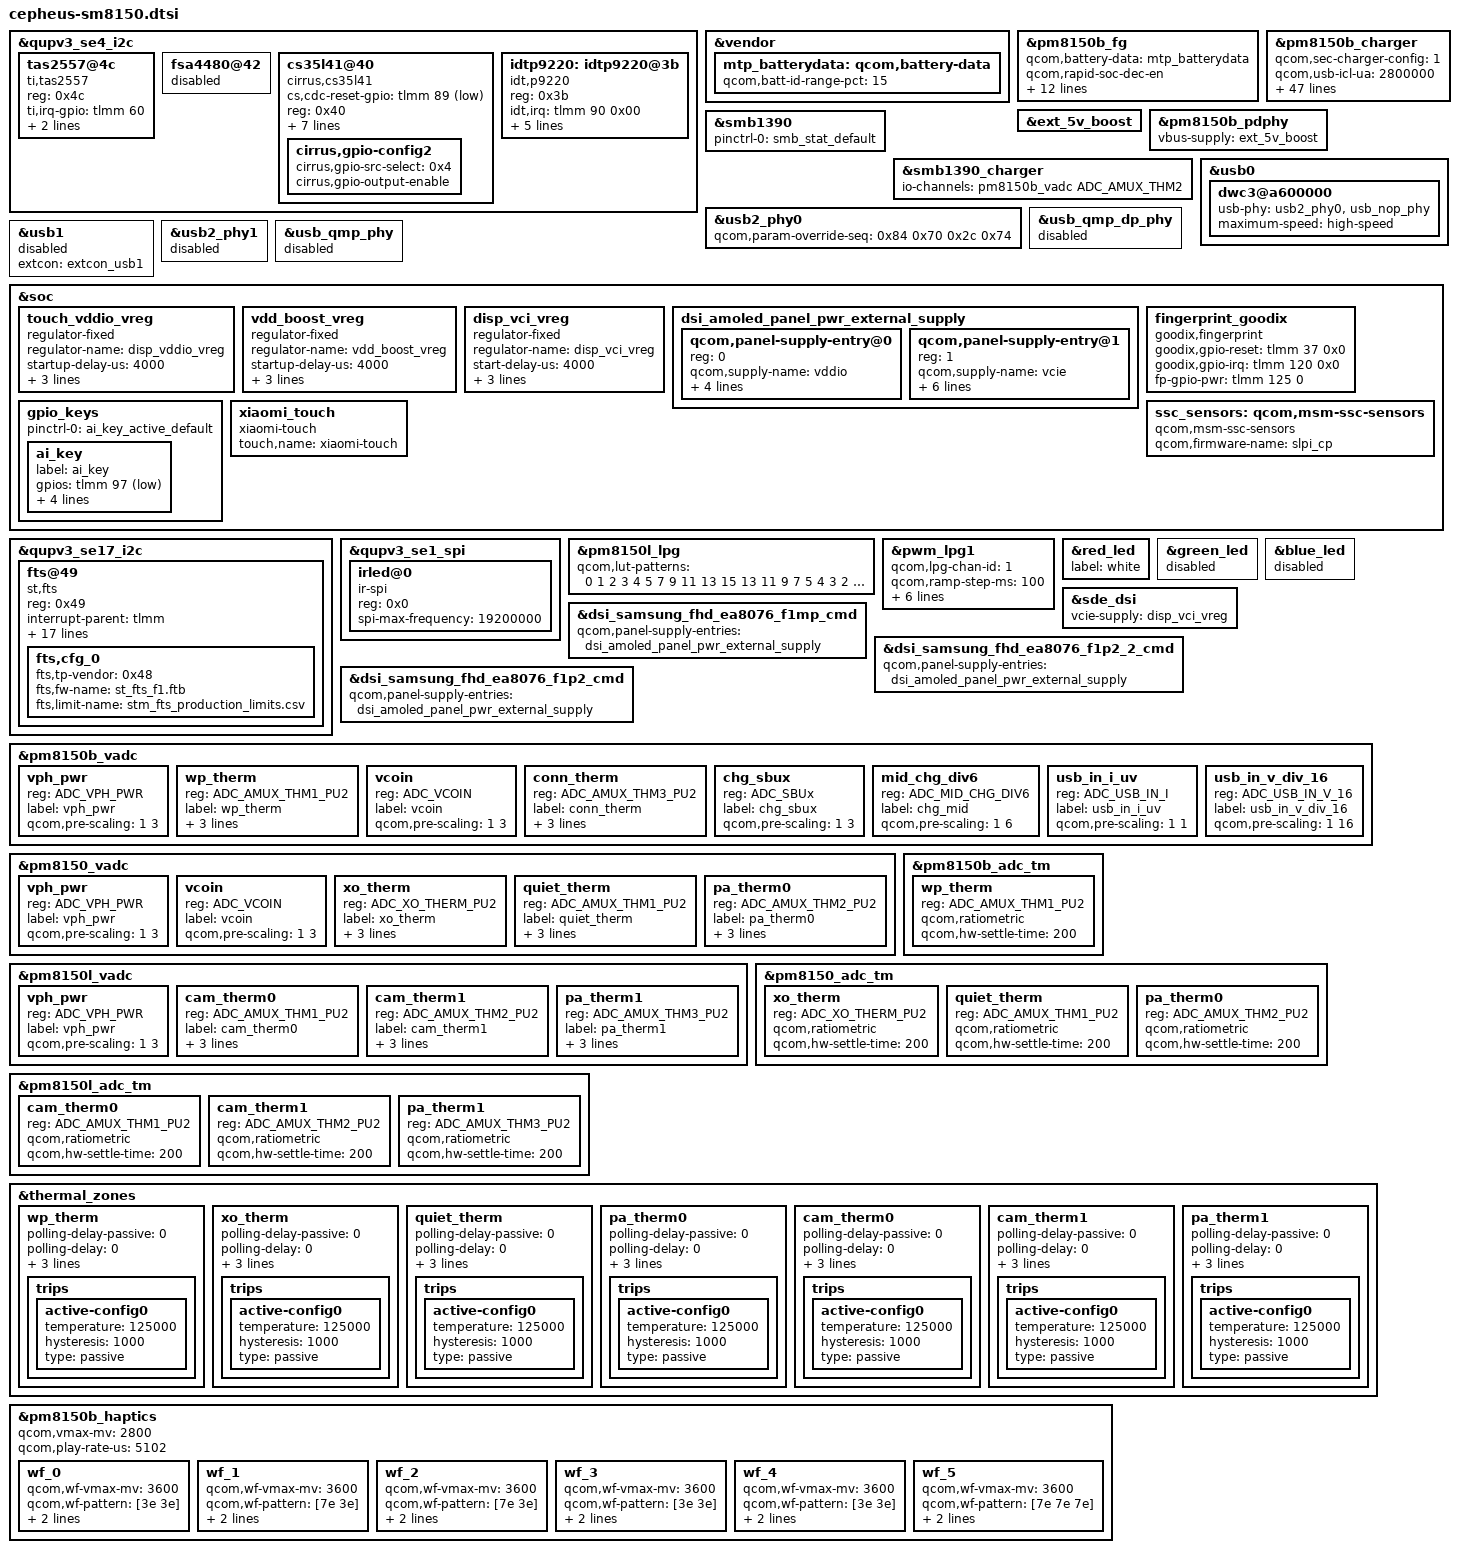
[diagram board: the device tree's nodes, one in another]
/*
this file is for attribution only of cepheus
And public attribution of xiaomi platforms(like F1 and so and)
*/
#include "cepheus-pinctrl.dtsi"
#include "xiaomi-sm8150-common.dtsi"
#include "cepheus-sm8150-camera-sensor-mtp.dtsi"

&qupv3_se4_i2c {
#include "smb1390.dtsi"
};

&vendor {
	mtp_batterydata: qcom,battery-data {
		qcom,batt-id-range-pct = <15>;
		#include "batterydata-F1-atl-3300mah.dtsi"
		#include "batterydata-F1-coslight-3300mah.dtsi"
		#include "fg-gen4-batterydata-alium-3600mah.dtsi"
	};
};

&pm8150b_fg {
	qcom,battery-data = <&mtp_batterydata>;
	qcom,rapid-soc-dec-en;
	qcom,fg-sys-term-current = <(-300)>;
	qcom,fg-cutoff-voltage = <3400>;
	qcom,fg-cutoff-current = <200>;
	qcom,fg-empty-voltage = <3100>;
	qcom,fg-batt-temp-delta = <6>;
	qcom,fg-force-load-profile;
	/* ESR fast calibration */
	qcom,fg-esr-timer-chg-fast = <0 7>;
	qcom,fg-esr-timer-dischg-fast = <0 7>;
	qcom,fg-esr-timer-chg-slow = <0 96>;
	qcom,fg-esr-timer-dischg-slow = <0 96>;
	qcom,fg-esr-cal-soc-thresh = <26 230>;
	qcom,fg-esr-cal-temp-thresh = <10 40>;
};

&pm8150b_charger {
	qcom,sec-charger-config = <1>;
	qcom,usb-icl-ua = <2800000>;
	qcom,fcc-max-ua = <4800000>;
	qcom,fv-max-uv = <4400000>;
	qcom,dc-icl-ua = <1000000>;
	qcom,auto-recharge-soc = <99>;
	qcom,chg-term-src = <1>;
	qcom,chg-term-current-ma = <(-220)>;
	qcom,chg-term-base-current-ma = <(-180)>;
	qcom,thermal-mitigation = <3000000 2800000 2600000 2400000 2200000 2100000 2000000
				   1800000 1600000 1500000 1400000 1200000 1000000 900000
				   800000 500000>;
	qcom,thermal-mitigation-icl
				= <2800000 2700000 2600000 2400000 2200000 2100000 2100000
				   2100000 1900000 1800000 1700000 1600000 1500000 1300000
				   1000000 750000>;
	qcom,thermal-mitigation-dcp
				= <1800000 1800000 1800000 1800000 1800000 1800000 1800000
				   1800000 1800000 1700000 1600000 1400000 1200000 1100000
				   1100000 1000000>;
	qcom,thermal-mitigation-qc2
				= <1500000 1500000 1500000 1500000 1450000 1400000 1350000
				   1300000 1300000 1200000 1000000 900000 850000 750000
				   650000 500000>;
	qcom,thermal-fcc-qc3-normal
				= <3200000 3000000 2800000 2600000 2500000 2400000 2300000
				   2200000 2100000 1800000 1600000 1400000 1200000 1000000
				   750000 750000>;
	qcom,thermal-fcc-qc3-cp
				= <3600000 3600000 3600000 3600000 3200000 3200000 3200000
				   3200000 3100000 2800000 2400000 2200000 2000000 1300000
				   750000 700000>;
	qcom,thermal-fcc-qc3-classb-cp
				= <4800000 4700000 4600000 4500000 4400000 4200000 3800000
				   3800000 3700000 3600000 3400000 3200000 3000000 2200000
				   1000000 700000>;
	qcom,thermal-mitigation-pd-base
				= <3000000 2800000 2600000 2500000 2500000 2500000 2500000
				   2500000 2500000 2400000 2200000 2000000 1600000 1300000
				   1000000 500000>;
	qcom,thermal-fcc-pps-cp
				= <4800000 4700000 4600000 4500000 4400000 4200000 3800000
				   3800000 3800000 3600000 3400000 3200000 3000000 2200000
				   1000000 750000>;
	qcom,thermal-mitigation-dc
				= <2100000 2000000 1800000 1600000 1400000 1200000 1100000
				   1000000 900000  800000  700000  600000  500000  400000
				   300000  200000>;
	qcom,thermal-mitigation-epp
				= <1200000 1200000 1200000 1100000 1100000 1000000 1000000
				   1000000 900000  700000  700000  600000  500000  400000
				   300000  200000>;
	qcom,thermal-mitigation-bpp-qc3
				= <1400000 1300000 1200000 1200000 1100000 1000000 900000
				   800000  700000  700000  700000  600000  500000  400000
				   300000  200000>;
	qcom,thermal-mitigation-bpp-qc2
				= <1100000 1100000 1100000 1100000 1100000 1000000 1000000
				   1000000 700000  700000  700000  600000  500000  400000
				   300000  200000>;
	qcom,thermal-mitigation-bpp
				= <1000000 1000000 1000000 1000000 1000000 1000000 1000000
				   1000000 900000  700000  700000  600000  500000 400000
				   300000  200000>;

	io-channels = <&pm8150b_vadc ADC_MID_CHG_DIV6>,
		      <&pm8150b_vadc ADC_USB_IN_V_16>,
		      <&pm8150b_vadc ADC_USB_IN_I>,
		      <&pm8150b_vadc ADC_SBUx>,
		      <&pm8150b_vadc ADC_VPH_PWR>,
		      <&pm8150b_vadc ADC_CHG_TEMP>;
	io-channel-names = "mid_voltage",
			   "usb_in_voltage",
			   "usb_in_current",
			   "sbux_res",
			   "vph_voltage",
			   "chg_temp";
	qcom,battery-data = <&mtp_batterydata>;
	dpdm-supply = <&usb2_phy0>;
	qcom,distinguish-qc-class-ab;
	qcom,sw-jeita-enable;
	qcom,wd-bark-time-secs = <16>;
	qcom,support-wireless;
};

&ext_5v_boost {
	status = "ok";
};

&pm8150b_pdphy {
	vbus-supply = <&ext_5v_boost>;
};

&qupv3_se4_i2c {
	status = "ok";
	tas2557@4c {
		compatible = "ti,tas2557";
		reg = <0x4c>;
		//ti,cdc-reset-gpio = <&tlmm 59 0>;
		ti,irq-gpio = <&tlmm 60 0>;
		ti,i2s-bits = <16>;
		ti,bypass-tmax = <0>;
	};

	fsa4480@42 {
		status = "disabled";
	};

	cs35l41@40 {
		#sound-dai-cells = <1>;
		compatible = "cirrus,cs35l41";
		cs,cdc-reset-gpio = <&tlmm 89 0x01>;
		reg = <0x40>;
		pinctrl-names = "cs35l41_irq_default";
		pinctrl-0 = <&cs35l41_int_default>;
		interrupt-parent = <&tlmm>;
		interrupts = <10 8>;

		cirrus,temp-warn_threshold = <3>;
		cirrus,boost-peak-milliamp = <4000>;
		cirrus,boost-ind-nanohenry = <1000>;
		cirrus,boost-cap-microfarad = <15>;
		cirrus,gpio-config2 {
			cirrus,gpio-src-select = <0x4>;
			cirrus,gpio-output-enable;
		};
	};

};

&smb1390 {
	pinctrl-names = "default";
	pinctrl-0 = <&smb_stat_default>;
	status = "ok";
};

&smb1390_charger {
	io-channels = <&pm8150b_vadc ADC_AMUX_THM2>;
	io-channel-names = "cp_die_temp";
	status = "ok";
};

&usb0 {
	dwc3@a600000 {
		usb-phy = <&usb2_phy0>, <&usb_nop_phy>;
		maximum-speed = "high-speed";
	};
};

&usb2_phy0 {
	qcom,param-override-seq =
		<0x84 0x70
		 0x2c 0x74>;
};

&usb_qmp_dp_phy {
	status = "disabled";
};

&usb1 {
	extcon = <&extcon_usb1>;
	status = "disabled";
};

&usb2_phy1 {
	status = "disabled";
};

&usb_qmp_phy {
	status = "disabled";
};

&soc {
	touch_vddio_vreg: touch_vddio_vreg {
		compatible = "regulator-fixed";
		regulator-name = "disp_vddio_vreg";
		startup-delay-us = <4000>;
		enable-active-high;
		regulator-boot-on;
		gpio = <&tlmm 84 0>;
	 };

	vdd_boost_vreg: vdd_boost_vreg {
		compatible = "regulator-fixed";
		regulator-name = "vdd_boost_vreg";
		startup-delay-us = <4000>;
		enable-active-high;
		regulator-always-on;
		gpio = <&pm8150b_gpios 5 0>;
	 };

	disp_vci_vreg: disp_vci_vreg {
		compatible = "regulator-fixed";
		regulator-name = "disp_vci_vreg";
		start-delay-us = <4000>;
		enable-active-high;
		regulator-boot-on;
		gpio = <&tlmm 21 0>;
	};

	dsi_amoled_panel_pwr_external_supply: dsi_amoled_panel_pwr_external_supply {
		#address-cells = <1>;
		#size-cells = <0>;

		qcom,panel-supply-entry@0 {
			reg = <0>;
			qcom,supply-name = "vddio";
			qcom,supply-min-voltage = <1800000>;
			qcom,supply-max-voltage = <1800000>;
			qcom,supply-enable-load = <62000>;
			qcom,supply-disable-load = <80>;
			//qcom,supply-post-on-sleep = <20>;
		};

		qcom,panel-supply-entry@1 {
			reg = <1>;
			qcom,supply-name = "vcie";
			qcom,supply-min-voltage = <3000000>;
			qcom,supply-max-voltage = <3000000>;
			qcom,supply-enable-load = <62000>;
			qcom,supply-disable-load = <80>;
			qcom,supply-post-on-sleep = <10>;
			qcom,supply-pre-off-sleep = <10>;
		};
	};

	fingerprint_goodix {
		compatible = "goodix,fingerprint";
		goodix,gpio-reset = <&tlmm 37 0x0>;
		goodix,gpio-irq = <&tlmm 120 0x0>;
		fp-gpio-pwr = <&tlmm 125 0>;
		status = "ok";
	};

	gpio_keys {
		pinctrl-0 = <&ai_key_active_default>;
		ai_key {
			label = "ai_key";
			gpios = <&tlmm 97 GPIO_ACTIVE_LOW>;
			linux,input-type = <1>;
			linux,code = <KEY_AI>;
			gpio-key,wakeup;
			debounce-interval = <39>;
		};
	};

	xiaomi_touch {
		compatible = "xiaomi-touch";
		status = "ok";
		touch,name = "xiaomi-touch";
	};
};

&qupv3_se17_i2c {
	status = "ok";
	fts@49 {
		compatible = "st,fts";
		reg = <0x49>;
		interrupt-parent = <&tlmm>;
		interrupts = <122 0x2008>;
		pinctrl-names = "pmx_ts_active", "pmx_ts_suspend";
		pinctrl-0 = <&ts_active>;
		pinctrl-1 = <&ts_int_suspend &ts_reset_suspend>;
		vdd-supply = <&touch_vddio_vreg>;
		avdd-supply = <&pm8150l_l1>;
		fts,pwr-reg-name = "avdd";
		fts,bus-reg-name = "vdd";
		fts,irq-gpio = <&tlmm 122 0x2008>;
		fts,irq-gpio-name = "fts_irq";
		fts,reset-gpio-enable;
		fts,reset-gpio = <&tlmm 12 0x00>;
		fts,reset-gpio-name = "fts_rst";
		fts,irq-flags = <0x2008>; /* IRQF_ONESHOT | IRQF_TRIGGER_LOW */
		fts,x-max = <1080>;
		fts,y-max = <2340>;
		fts,default-fw-name = "st_fts_f1.ftb";
		fts,config-array-size = <1>;
		fts,cfg_0 {
			fts,tp-vendor = <0x48>;
			fts,fw-name = "st_fts_f1.ftb";
			fts,limit-name = "stm_fts_production_limits.csv";
		};
	};
};

/*
&qupv3_se9_i2c {
	status = "ok";
	idtp9220: idtp9220@3b {
		compatible = "idt,p9220";
		reg = <0x3b>;
		idt,irq = <&tlmm 90 0x00>;
		idt,enable = <&tlmm 104 0x00>;
		interrupt-parent = <&tlmm>;
		interrupts = <90 0>;
		interrupt-names = "idt_irq";
		pinctrl-names = "idt_active", "idt_suspend";
		pinctrl-0 = <&idt_int_active &idt_enable_active>;
		pinctrl-1 = <&idt_int_suspend &idt_enable_suspend>;
	};
	wl_charger_rx1618@60 {
		compatible = "nuvolta,wl_charger_rx1618";
		reg = <0x60>;
		rx1618_irq_gpio = <&tlmm 90 0x00>;
		interrupt-parent = <&tlmm>;
		interrupts = <90 0>;
		interrupt-names = "wl_irq";
	};
};
*/


&qupv3_se4_i2c {
	status = "ok";
	idtp9220: idtp9220@3b {
		compatible = "idt,p9220";
		reg = <0x3b>;
		idt,irq = <&tlmm 90 0x00>;
		idt,enable = <&tlmm 104 0x00>;
		idt,wpc-det = <&pm8150b_gpios 7 GPIO_ACTIVE_HIGH>;
		pinctrl-names = "default", "idt_active", "idt_suspend";
		pinctrl-0 = <&power_good_default>;
		pinctrl-1 = <&idt_int_active &idt_enable_active>;
		pinctrl-2 = <&idt_int_suspend &idt_enable_suspend>;
	};
};


&qupv3_se1_spi {
	status = "ok";
	irled@0 {
		compatible = "ir-spi";
		reg = <0x0>;
		status = "ok";
		spi-max-frequency = <19200000>;
	};
};

&pm8150l_lpg {
	qcom,lut-patterns = <0 1 2 3 4 5 7 9 11 13 15
				13 11 9 7 5 4 3 2 1 0>;
};

&pwm_lpg1 {
	qcom,lpg-chan-id = <1>;
	qcom,ramp-step-ms = <100>;
	qcom,ramp-pause-hi-count = <2>;
	qcom,ramp-pause-lo-count = <2>;
	qcom,ramp-low-index = <0>;
	qcom,ramp-high-index = <20>;
	qcom,ramp-from-low-to-high;
	qcom,ramp-pattern-repeat;
};

&red_led {
	label = "white";
};

&green_led {
	status = "disabled";
};

&blue_led {
	status = "disabled";
};

&sde_dsi {
	vcie-supply = <&disp_vci_vreg>;
};

&dsi_samsung_fhd_ea8076_f1mp_cmd {
	qcom,panel-supply-entries = <&dsi_amoled_panel_pwr_external_supply>;
};

&dsi_samsung_fhd_ea8076_f1p2_2_cmd {
	qcom,panel-supply-entries = <&dsi_amoled_panel_pwr_external_supply>;
};

&dsi_samsung_fhd_ea8076_f1p2_cmd {
	qcom,panel-supply-entries = <&dsi_amoled_panel_pwr_external_supply>;
};

&pm8150b_vadc {
	vph_pwr {
		reg = <ADC_VPH_PWR>;
		label = "vph_pwr";
		qcom,pre-scaling = <1 3>;
	};

	wp_therm {
		reg = <ADC_AMUX_THM1_PU2>;
		label = "wp_therm";
		qcom,ratiometric;
		qcom,hw-settle-time = <200>;
		qcom,pre-scaling = <1 1>;
	};

	vcoin {
		reg = <ADC_VCOIN>;
		label = "vcoin";
		qcom,pre-scaling = <1 3>;
	};

	conn_therm {
		reg = <ADC_AMUX_THM3_PU2>;
		label = "conn_therm";
		qcom,ratiometric;
		qcom,hw-settle-time = <200>;
		qcom,pre-scaling = <1 1>;
	};

	chg_sbux {
		reg = <ADC_SBUx>;
		label = "chg_sbux";
		qcom,pre-scaling = <1 3>;
	};

	mid_chg_div6 {
		reg = <ADC_MID_CHG_DIV6>;
		label = "chg_mid";
		qcom,pre-scaling = <1 6>;
	};

	usb_in_i_uv {
		reg = <ADC_USB_IN_I>;
		label = "usb_in_i_uv";
		qcom,pre-scaling = <1 1>;
	};

	usb_in_v_div_16 {
		reg = <ADC_USB_IN_V_16>;
		label = "usb_in_v_div_16";
		qcom,pre-scaling = <1 16>;
	};
};

&pm8150_vadc {
	vph_pwr {
		reg = <ADC_VPH_PWR>;
		label = "vph_pwr";
		qcom,pre-scaling = <1 3>;
	};

	vcoin {
		reg = <ADC_VCOIN>;
		label = "vcoin";
		qcom,pre-scaling = <1 3>;
	};

	xo_therm {
		reg = <ADC_XO_THERM_PU2>;
		label = "xo_therm";
		qcom,ratiometric;
		qcom,hw-settle-time = <200>;
		qcom,pre-scaling = <1 1>;
	};

	quiet_therm {
		reg = <ADC_AMUX_THM1_PU2>;
		label = "quiet_therm";
		qcom,ratiometric;
		qcom,hw-settle-time = <200>;
		qcom,pre-scaling = <1 1>;
	};

	pa_therm0 {
		reg = <ADC_AMUX_THM2_PU2>;
		label = "pa_therm0";
		qcom,ratiometric;
		qcom,hw-settle-time = <200>;
		qcom,pre-scaling = <1 1>;
	};
};

&pm8150l_vadc {
	vph_pwr {
		reg = <ADC_VPH_PWR>;
		label = "vph_pwr";
		qcom,pre-scaling = <1 3>;
	};

	cam_therm0 {
		reg = <ADC_AMUX_THM1_PU2>;
		label = "cam_therm0";
		qcom,ratiometric;
		qcom,hw-settle-time = <200>;
		qcom,pre-scaling = <1 1>;
	};

	cam_therm1 {
		reg = <ADC_AMUX_THM2_PU2>;
		label = "cam_therm1";
		qcom,ratiometric;
		qcom,hw-settle-time = <200>;
		qcom,pre-scaling = <1 1>;
	};

	pa_therm1 {
		reg = <ADC_AMUX_THM3_PU2>;
		label = "pa_therm1";
		qcom,ratiometric;
		qcom,hw-settle-time = <200>;
		qcom,pre-scaling = <1 1>;
	};
};

&pm8150b_adc_tm {
	wp_therm {
		reg = <ADC_AMUX_THM1_PU2>;
		qcom,ratiometric;
		qcom,hw-settle-time = <200>;
	};
};

&pm8150_adc_tm {
	xo_therm {
		reg = <ADC_XO_THERM_PU2>;
		qcom,ratiometric;
		qcom,hw-settle-time = <200>;
	};
	quiet_therm {
		reg = <ADC_AMUX_THM1_PU2>;
		qcom,ratiometric;
		qcom,hw-settle-time = <200>;
	};

	pa_therm0 {
		reg = <ADC_AMUX_THM2_PU2>;
		qcom,ratiometric;
		qcom,hw-settle-time = <200>;
	};
};

&pm8150l_adc_tm {
	cam_therm0 {
		reg = <ADC_AMUX_THM1_PU2>;
		qcom,ratiometric;
		qcom,hw-settle-time = <200>;
	};

	cam_therm1 {
		reg = <ADC_AMUX_THM2_PU2>;
		qcom,ratiometric;
		qcom,hw-settle-time = <200>;
	};

	pa_therm1 {
		reg = <ADC_AMUX_THM3_PU2>;
		qcom,ratiometric;
		qcom,hw-settle-time = <200>;
	};
};

&thermal_zones {
	wp_therm {
		polling-delay-passive = <0>;
		polling-delay = <0>;
		thermal-governor = "user_space";
		thermal-sensors = <&pm8150b_adc_tm ADC_AMUX_THM1_PU2>;
		trips {
			active-config0 {
				temperature = <125000>;
				hysteresis = <1000>;
				type = "passive";
			};
		};
	};

	xo_therm {
		polling-delay-passive = <0>;
		polling-delay = <0>;
		thermal-governor = "user_space";
		thermal-sensors = <&pm8150_adc_tm ADC_XO_THERM_PU2>;
		trips {
			active-config0 {
				temperature = <125000>;
				hysteresis = <1000>;
				type = "passive";
			};
		};
	};

	quiet_therm {
		polling-delay-passive = <0>;
		polling-delay = <0>;
		thermal-governor = "user_space";
		thermal-sensors = <&pm8150_adc_tm ADC_AMUX_THM1_PU2>;
		trips {
			active-config0 {
				temperature = <125000>;
				hysteresis = <1000>;
				type = "passive";
			};
		};
	};

	pa_therm0 {
		polling-delay-passive = <0>;
		polling-delay = <0>;
		thermal-governor = "user_space";
		thermal-sensors = <&pm8150_adc_tm ADC_AMUX_THM2_PU2>;
		trips {
			active-config0 {
				temperature = <125000>;
				hysteresis = <1000>;
				type = "passive";
			};
		};
	};

	cam_therm0 {
		polling-delay-passive = <0>;
		polling-delay = <0>;
		thermal-governor = "user_space";
		thermal-sensors = <&pm8150l_adc_tm ADC_AMUX_THM1_PU2>;
		trips {
			active-config0 {
				temperature = <125000>;
				hysteresis = <1000>;
				type = "passive";
			};
		};
	};

	cam_therm1 {
		polling-delay-passive = <0>;
		polling-delay = <0>;
		thermal-governor = "user_space";
		thermal-sensors = <&pm8150l_adc_tm ADC_AMUX_THM2_PU2>;
		trips {
			active-config0 {
				temperature = <125000>;
				hysteresis = <1000>;
				type = "passive";
			};
		};
	};

	pa_therm1 {
		polling-delay-passive = <0>;
		polling-delay = <0>;
		thermal-governor = "user_space";
		thermal-sensors = <&pm8150l_adc_tm ADC_AMUX_THM3_PU2>;
		trips {
			active-config0 {
				temperature = <125000>;
				hysteresis = <1000>;
				type = "passive";
			};
		};
	};
};

&pm8150b_haptics {
	qcom,vmax-mv = <2800>;
	qcom,play-rate-us = <5102>;

	wf_0 {
		/* CLICK */
		qcom,wf-vmax-mv = <3600>;
		qcom,wf-pattern = [3e 3e];
		qcom,wf-brake-pattern = [02 01 00 00];
		qcom,wf-play-rate-us = <5102>;
	};
	wf_1 {
		/* DOUBLE CLICK */
		qcom,wf-vmax-mv = <3600>;
		qcom,wf-pattern = [7e 3e];
		qcom,wf-brake-pattern = [03 01 01 00];
		qcom,wf-play-rate-us = <5102>;
	};
	wf_2 {
		/* TICK */
		qcom,wf-vmax-mv = <3600>;
		qcom,wf-pattern = [7e 3e];
		qcom,wf-brake-pattern = [03 01 01 00];
		qcom,wf-play-rate-us = <5102>;
	};
	wf_3 {
		/* THUD */
		qcom,wf-vmax-mv = <3600>;
		qcom,wf-pattern = [3e 3e];
		qcom,wf-brake-pattern = [02 01 00 00];
		qcom,wf-play-rate-us = <5102>;
	};
	wf_4 {
		/* POP */
		qcom,wf-vmax-mv = <3600>;
		qcom,wf-pattern = [3e 3e];
		qcom,wf-brake-pattern = [02 01 00 00];
		qcom,wf-play-rate-us = <5102>;
	};
	wf_5 {
		/* HEAVY CLICK */
		qcom,wf-vmax-mv = <3600>;
		qcom,wf-pattern = [7e 7e 7e];
		qcom,wf-brake-pattern = [03 03 01 00];
		qcom,wf-play-rate-us = <5102>;
	};
};

&soc {
	ssc_sensors: qcom,msm-ssc-sensors {
		compatible = "qcom,msm-ssc-sensors";
		status = "ok";
		qcom,firmware-name = "slpi_cp";
	};
};
